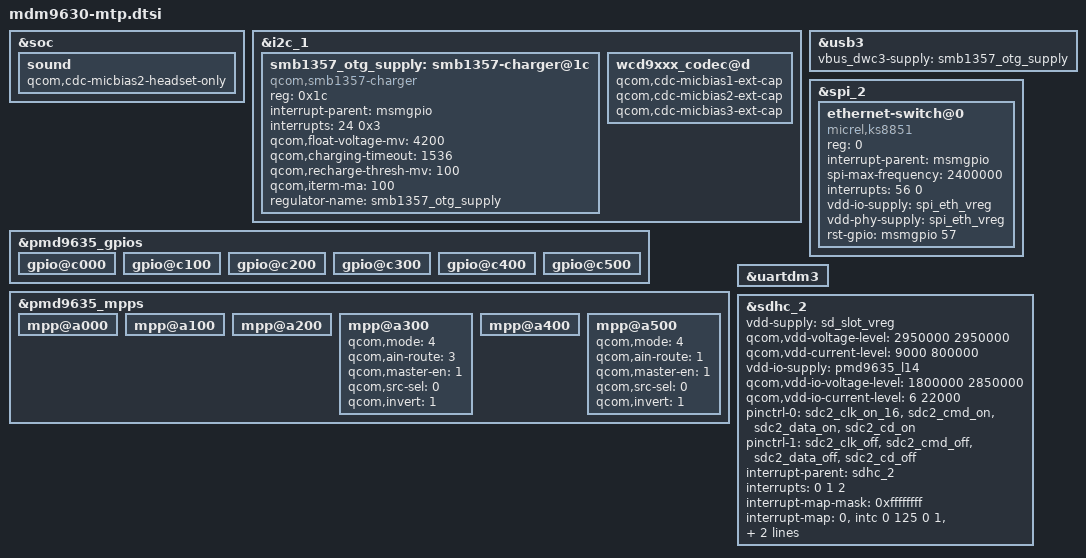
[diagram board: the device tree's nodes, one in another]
/* Copyright (c) 2013-2014, The Linux Foundation. All rights reserved.
 *
 * This program is free software; you can redistribute it and/or modify
 * it under the terms of the GNU General Public License version 2 and
 * only version 2 as published by the Free Software Foundation.
 *
 * This program is distributed in the hope that it will be useful,
 * but WITHOUT ANY WARRANTY; without even the implied warranty of
 * MERCHANTABILITY or FITNESS FOR A PARTICULAR PURPOSE.  See the
 * GNU General Public License for more details.
 */

&soc {
	sound {
		qcom,cdc-micbias2-headset-only;
	};
};

&i2c_1 {
	smb1357_otg_supply: smb1357-charger@1c {
		compatible = "qcom,smb1357-charger";
		reg = <0x1c>;
		interrupt-parent = <&msmgpio>;
		interrupts = <24 0x3>;	/* MDM GPIO 24 */
		qcom,float-voltage-mv = <4200>;
		qcom,charging-timeout = <1536>;
		qcom,recharge-thresh-mv = <100>;
		qcom,iterm-ma = <100>;
		regulator-name = "smb1357_otg_supply";
	};

	wcd9xxx_codec@d{
		qcom,cdc-micbias1-ext-cap;
		qcom,cdc-micbias2-ext-cap;
		qcom,cdc-micbias3-ext-cap;
	};
};

&usb3 {
	vbus_dwc3-supply = <&smb1357_otg_supply>; /* Host 5V VBUS from SMB1357 regulator */
};

&spi_2 {
	ethernet-switch@0 {
		compatible = "micrel,ks8851";
		reg = <0>;
		interrupt-parent = <&msmgpio>;
		spi-max-frequency = <2400000>;
		interrupts = <56 0>;
		vdd-io-supply = <&spi_eth_vreg>;
		vdd-phy-supply = <&spi_eth_vreg>;
		rst-gpio = <&msmgpio 57 0>;
	};
};

&pmd9635_gpios {
	gpio@c000 { /* GPIO 1 */
	};

	gpio@c100 { /* GPIO 2 */
	};

	gpio@c200 { /* GPIO 3 */
		status = "ok";
	};

	gpio@c300 { /* GPIO 4 */
		status = "ok";
	};

	gpio@c400 { /* GPIO 5 */
	};

	gpio@c500 { /* GPIO 6 */
	};
};

&pmd9635_mpps {
	mpp@a000 { /* MPP 1 */
		status = "ok";
	};

	mpp@a100 { /* MPP 2 */
		status = "ok";
	};

	mpp@a200 { /* MPP 3 */
		status = "ok";
	};

	mpp@a300 { /* MPP 4 */
		/* VADC channel 19 */
		qcom,mode = <4>;
		qcom,ain-route = <3>; /* AMUX 8 */
		qcom,master-en = <1>;
		qcom,src-sel = <0>; /* Function constant */
		qcom,invert = <1>;
		status = "ok";
	};

	mpp@a400 { /* MPP 5 */
	};

	mpp@a500 { /* MPP 6 */
		/* channel 21 */
		qcom,mode = <4>;
		qcom,ain-route = <1>; /* AMUX 6 */
		qcom,master-en = <1>;
		qcom,src-sel = <0>; /* Function constant */
		qcom,invert = <1>;
		status = "ok";
	};
};

&uartdm3{
	status = "ok";
};

&sdhc_2 {
	vdd-supply = <&sd_slot_vreg>;
	qcom,vdd-voltage-level = <2950000 2950000>;
	qcom,vdd-current-level = <9000 800000>;

	vdd-io-supply = <&pmd9635_l14>;
	qcom,vdd-io-voltage-level = <1800000 2850000>;
	qcom,vdd-io-current-level = <6 22000>;

	pinctrl-names = "active", "sleep";
	pinctrl-0 = <&sdc2_clk_on_16 &sdc2_cmd_on &sdc2_data_on &sdc2_cd_on>;
	pinctrl-1 = <&sdc2_clk_off &sdc2_cmd_off &sdc2_data_off &sdc2_cd_off>;

	#address-cells = <0>;
	interrupt-parent = <&sdhc_2>;
	interrupts = <0 1 2>;
	#interrupt-cells = <1>;
	interrupt-map-mask = <0xffffffff>;
	interrupt-map = <0 &intc 0 125 0
			1 &intc 0 221 0
			2 &msmgpio 50 0x3>;
	interrupt-names = "hc_irq", "pwr_irq", "status_irq";

	cd-gpios = <&msmgpio 50 0x1>;

	status = "ok";
};
